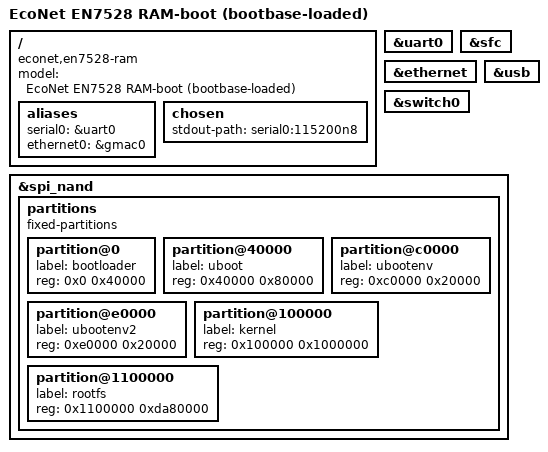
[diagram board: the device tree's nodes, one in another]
// SPDX-License-Identifier: GPL-2.0+
/dts-v1/;

#include "econet,en7528.dtsi"

/ {
	model = "EcoNet EN7528 RAM-boot (bootbase-loaded)";
	compatible = "econet,en7528-ram", "econet,en7528";

	aliases {
		serial0 = &uart0;
		ethernet0 = &gmac0;
	};

	chosen {
		stdout-path = "serial0:115200n8";
	};
};

&uart0 {
	status = "okay";
};

&sfc {
	status = "okay";
};

&ethernet {
	status = "okay";
};

&switch0 {
	status = "okay";
};

&usb {
	status = "okay";
};

/* Flash partition map (labels unused on the RAM-boot path). */
&spi_nand {
	partitions {
		compatible = "fixed-partitions";
		#address-cells = <1>;
		#size-cells = <1>;

		partition@0 {
			label = "bootloader";
			reg = <0x0 0x40000>;
		};
		partition@40000 {
			label = "uboot";
			reg = <0x40000 0x80000>;
		};
		partition@c0000 {
			label = "ubootenv";
			reg = <0xc0000 0x20000>;
		};
		partition@e0000 {
			label = "ubootenv2";
			reg = <0xe0000 0x20000>;
		};
		partition@100000 {
			label = "kernel";
			reg = <0x100000 0x1000000>;
		};
		partition@1100000 {
			label = "rootfs";
			reg = <0x1100000 0xda80000>;
		};
	};
};
